# Canonical register map
File version: 1
Normalization fixture
Registers are 8-bit, read-write, reset 0x0 unless marked. A register's access mark holds for its fields unless they carry their own. Offsets are from the block's base; lines under a group give offsets from that group; [hi:lo] are bit positions; {n}, {i} and the like mark numbered series; 'fields as' and 'values as' point back to an identical list; <NAME> marks a mode.

## Memory map
0x00004000 TIMER size 0x100
0x00005000 TIMER2 size 0x100
{0x6000+0x100*n} PORT{n} (n=0..1) — ports

## Interrupts
4 TIM (TIMER) — timer interrupt

## TIMER
Base 0x00004000
Same registers: TIMER2 0x00005000
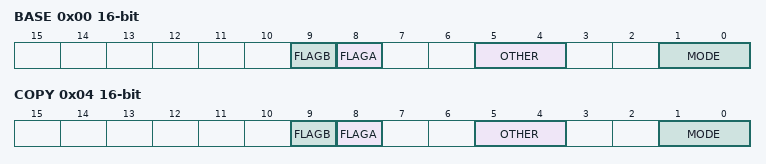
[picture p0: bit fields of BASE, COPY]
0x00 BASE 16-bit (alternate view of COPY)
  [all] fields
    0=OFF; 1=ON
  [8] FLAG{x} (x=A,B; step 1)
  [5:4] OTHER write-1-clears read-clears
  [1:0] MODE write-1-clears read-clears
0x04 COPY 16-bit ro — base
  [all] fields
    0=OFF; 1=ON
  [8] FLAG{x} (x=A,B; step 1)
  [5:4] OTHER rw write-1-clears read-clears
  [1:0] MODE rw write-1-clears read-clears
{0x8+4i} DATA{i} (i=2..4)
0x30 MORE%s
{0x80+0x20*i} CH[{i}] (i=0..1) group (alternate view of ALT)
  0x04 NEST group
    0x02 CTRL 4-bit wo
    0x03 STATUS wo
0xC0 ALT[%s] group
  0x04 NEST group
    0x02 CTRL 4-bit wo
    0x03 STATUS wo

## PORT{n} — ports
Base 0x00006000; array of 2, step 0x100
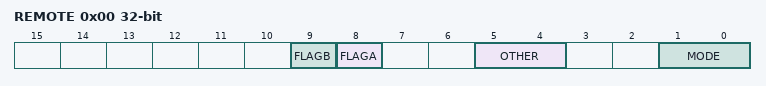
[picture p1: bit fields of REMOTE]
0x00 REMOTE 32-bit — base
  [all] fields
    0=OFF; 1=ON
  [8] FLAG{x} (x=A,B; step 1)
  [5:4] OTHER write-1-clears read-clears
  [1:0] MODE write-1-clears read-clears
